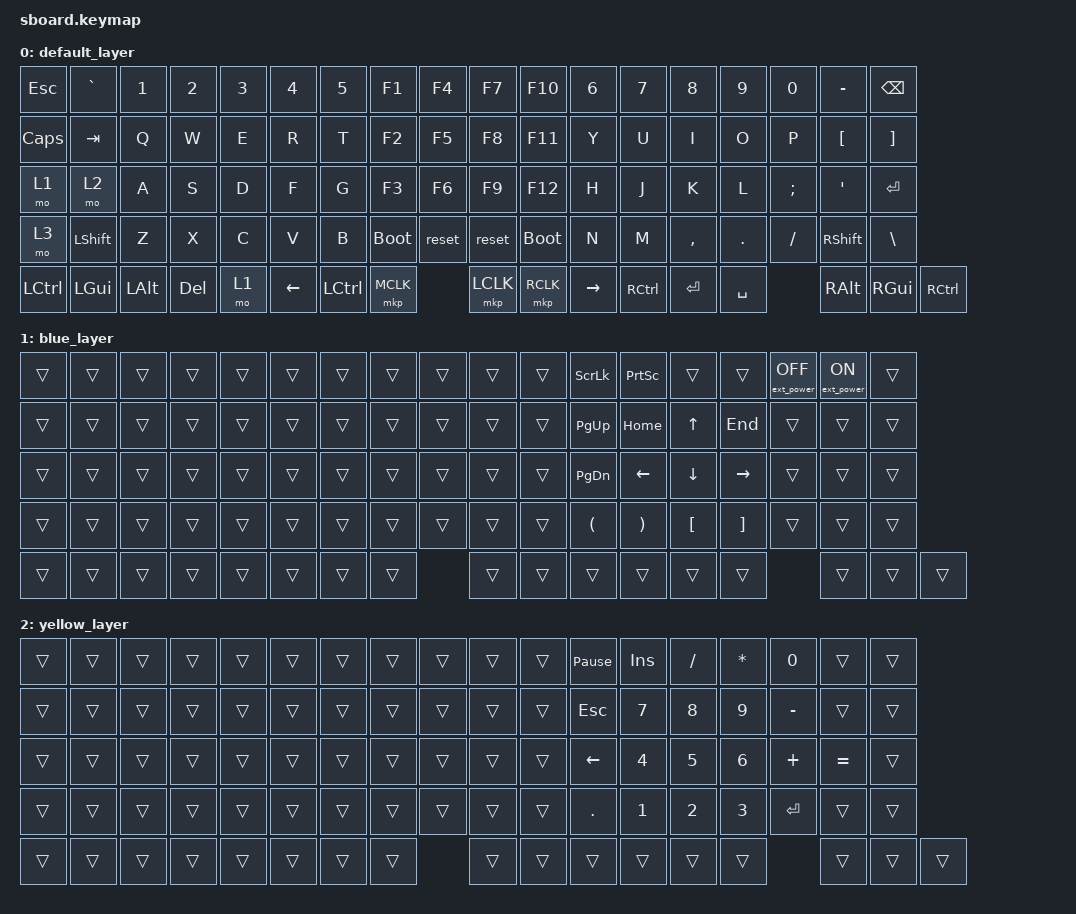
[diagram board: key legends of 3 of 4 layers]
#include <behaviors.dtsi>
#include <dt-bindings/zmk/keys.h>
#include <dt-bindings/zmk/bt.h>
#include <dt-bindings/zmk/ext_power.h>
#include <dt-bindings/zmk/mouse.h>
#include <dt-bindings/zmk/outputs.h>
#include <dt-bindings/zmk/ext_power.h>


#define BASE    0
#define BLUE    1
#define YELLOW  2
#define SETTING 3

/ {
    keymap {
        compatible = "zmk,keymap";

        default_layer {
// -------------------------------------------------------------------------------------------------------------------------------------
// |  ESC  |  `    |  1  |  2   |  3   |  4   |  5   |   F1   |  F4 |          | F7 | F10  |  6   |  7  |  8  |  9  |  0  |  -  |BKSP  |
// | CAPS  | TAB   |  Q  |  W   |  E   |  R   |  T   |   F2   |  F5 |          | F8 | F11  |  Y   |  U  |  I  |  O  |  p  |  [  |  ]   |    
// |  FnB  | FnY   |  A  |  S   |  D   |  F   |  G   |   F3   |  F6 |          | F9 | F12  |  H   |  J  |  K  |  L  |  ;  |  '  |Enter |    
// | Tri   | SHIFT |  Z  |  X   |  C   |  V   |  B   |   __   |  __ |          | -- | --   |  N   |  M  |  ,  |  .  |  /  |SHIFT|  \   |
// | CTRL  | GUI   | ALT |      |      |      |      |        |     |          |    |      |      |     |     |     | ALT |GUI  | CTRL |
// |       |       |     |      |      |      |      |   FnB  | Del |          |ENT |Space |
// |       |       |     |      |      |      |      |  Ctrl  |  __ |          |->  |Ctrl  |   
            bindings = <
&kp ESC     &kp GRAVE  &kp N1   &kp N2    &kp N3   &kp N4   &kp N5  &kp F1  &kp F4       &kp F7      &kp F10      &kp N6  &kp N7  &kp N8    &kp N9  &kp N0   &kp MINUS &kp BSPC
&kp CAPS    &kp TAB    &kp Q    &kp W     &kp E    &kp R    &kp T   &kp F2  &kp F5       &kp F8      &kp F11     &kp Y   &kp U   &kp I     &kp O   &kp P    &kp LBKT  &kp RBKT
&mo 1       &mo 2      &kp A    &kp S     &kp D    &kp F    &kp G   &kp F3  &kp F6       &kp F9      &kp F12     &kp H   &kp J   &kp K     &kp L   &kp SEMI &kp APOS  &kp ENTER
&mo 3       &kp LSHFT  &kp Z    &kp X     &kp C    &kp V    &kp B   &bootloader &reset   &reset      &bootloader &kp N   &kp M   &kp COMMA &kp DOT &kp SLASH &kp RSHIFT &kp BSLH
&kp LCTRL   &kp LGUI   &kp LALT &kp DEL   &mo 1    &kp LEFT &kp LCTRL &mkp MCLK          &mkp LCLK   &mkp RCLK   &kp RIGHT &kp RCTRL &kp ENTER &kp SPACE &kp RALT &kp RGUI &kp RCTRL                                                 
            >;

            sensor-bindings =  <&mw MW_UP(8) MW_DN(8)>;
            trackball-bindings = <&tmv>;
        };

        blue_layer {                
            bindings = <
&trans      &trans  &trans  &trans  &trans    &trans    &trans  &trans  &trans           &trans  &trans  &kp SLCK     &kp PSCRN    &trans    &trans   &ext_power EP_OFF  &ext_power EP_ON  &trans
&trans      &trans  &trans  &trans  &trans    &trans    &trans  &trans  &trans           &trans  &trans  &kp PG_UP    &kp HOME     &kp UP    &kp END  &trans  &trans  &trans
&trans      &trans  &trans  &trans  &trans    &trans    &trans  &trans  &trans           &trans  &trans  &kp PG_DN    &kp LEFT     &kp DOWN  &kp RIGHT &trans  &trans  &trans
&trans      &trans  &trans  &trans  &trans    &trans    &trans  &trans  &trans           &trans  &trans  &kp LPAR     &kp RPAR     &kp LBKT  &kp RBKT &trans  &trans  &trans
&trans      &trans  &trans  &trans  &trans    &trans    &trans  &trans                   &trans  &trans  &trans       &trans       &trans    &trans   &trans  &trans  &trans
            >;

            sensor-bindings =  <&mw MW_UP(8) MW_DN(8)>;
            trackball-bindings = <&tmv>;
        };

        yellow_layer {            
            bindings = <
&trans      &trans  &trans  &trans  &trans    &trans    &trans  &trans  &trans           &trans  &trans  &kp PAUSE_BREAK &kp INS   &kp SLASH &kp STAR &kp N0     &trans   &trans
&trans      &trans  &trans  &trans  &trans    &trans    &trans  &trans  &trans           &trans  &trans  &kp ESC      &kp N7       &kp N8    &kp N9   &kp MINUS  &trans   &trans
&trans      &trans  &trans  &trans  &trans    &trans    &trans  &trans  &trans           &trans  &trans  &kp LEFT     &kp N4       &kp N5    &kp N6   &kp PLUS   &kp EQUAL &trans
&trans      &trans  &trans  &trans  &trans    &trans    &trans  &trans  &trans           &trans  &trans  &kp DOT      &kp N1       &kp N2    &kp N3   &kp ENTER  &trans   &trans 
&trans      &trans  &trans  &trans  &trans    &trans    &trans  &trans                   &trans  &trans  &trans       &trans       &trans    &trans   &trans     &trans   &trans
            >;

            sensor-bindings =  <&mw MW_UP(8) MW_DN(8)>;
            trackball-bindings = <&tmv>;
        };

        setting_layer {                 
            bindings = <
&bt BT_CLR  &out OUT_TOG &bt BT_SEL 0 &bt BT_SEL 1 &bt BT_SEL 2 &bt BT_SEL 3 &bt BT_SEL 4 &bt BT_SEL 5 &trans &trans &trans &trans    &trans      &trans     &trans   &trans    &trans
&trans      &trans   &trans &trans &trans    &trans     &trans  &trans  &trans            &trans      &trans &trans  &trans       &trans      &trans     &trans   &trans    &trans
&trans      &trans   &trans &trans &trans    &trans     &trans  &trans  &trans            &trans      &trans &trans  &trans       &trans      &trans     &trans   &trans    &trans
&trans      &trans   &trans &trans &trans    &trans     &trans  &trans  &trans            &trans      &trans &trans  &trans       &trans      &trans     &trans   &trans    &trans 
&trans      &trans   &trans &bt BT_CLR &trans &trans    &trans  &trans                    &trans      &trans &trans  &trans       &trans      &trans     &trans   &trans    &trans
            >;

            sensor-bindings = <&inc_dec_kp C_VOL_UP C_VOL_DN>;
            trackball-bindings = <&tmv>;
        };
    };
};



// Allow USB logging
&usbd {
	status = "okay";
	cdc_acm_uart: cdc_acm_uart {
		compatible = "zephyr,cdc-acm-uart";
		label = "CDC_ACM_0";
	};
};
